# evalsoc register map
Vendor: Nuclei; Series: Nuclei Evaluation SoC
CPU: Evalsoc, little endian
Registers are 32-bit, read-write, reset 0x0 unless marked. A register's access mark holds for its fields unless they carry their own. Offsets are from the block's base; [hi:lo] are bit positions; {n}, {i} and the like mark numbered series.

## TIMER — Address space of TIMER unit. The Timer Unit (TIMER) is used to generate the Timer Interrupt and Software Interrupt in Nuclei Processor Core.
Base 0x18030000
0x00 mtime_lo — Reflect the lower 32-bit value of mtime. Shadow copy of MTIME in CLINT mode.
  [31:0] mtime_lo — Lower 32-bit value of mtime.
0x04 mtime_hi — Reflect the upper 32-bit value of mtime. Shadow copy of MTIME in CLINT mode.
  [31:0] mtime_hi — Upper 32-bit value of mtime.
0x08 mtimecmp_lo — Set the lower 32-bit value of mtimecmp. Shadow copy of MTIMECMP for 1st hart in CLINT mode.
  [31:0] mtimecmp_lo — Lower 32-bit value of mtimecmp.
0x0C mtimecmp_hi — Set the upper 32-bit value of mtimecmp. Shadow copy of MTIMECMP for 1st hart in CLINT mode.
  [31:0] mtimecmp_hi — Upper 32-bit value of mtimecmp.
0xFEC mtime_srw_ctrl — Control S-mode can access timer registers or not.
  [0] SRW — 0: S-Mode can read/write timer registers, 1: S-Mode cannot read/write timer registers
0xFF0 msftrst — Generate soft-reset request.
  [31] MSFTRST — Write 0x80000a5f to generate Soft-Reset Request.
0xFF4 setssip wo — Generate the S-mode Software Interrupt for the local hart.
  [31:0] setssip — Write 1 to trigger edge Supervisor Software Interrupt, read returns 0.
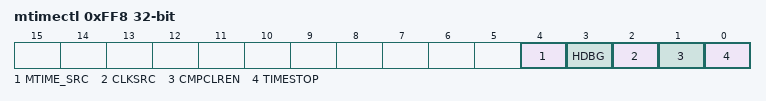
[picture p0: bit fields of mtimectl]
0xFF8 mtimectl — Control the behaviors of timer counting.
  [4] MTIME_SRC — MTIME source select. 0: timer unit mtime, 1: Soc mtime.
  [3] HDBG — Halt-on-debug control. When set, stoptime in dcsr halts the timer counter in debug mode.
  [2] CLKSRC — 1: core_aon_clk, 0: mtime_toggle_a
  [1] CMPCLREN — 1: mtime cleared to zero after timer interrupt, 0: mtime increments normally
  [0] TIMESTOP — 1: timer paused, 0: timer increments normally
0xFFC msip — Generate the M-mode Software Interrupt for the local hart.
  [0] MSIP — Write 1 to generate M-mode software interrupt, write 0 to clear.
{0x1000+4i} msip{i} (i=0..7) — M-mode Software Interrupt for Hart {i}.
  [31:0] MSIP — Write 1 to generate M-mode software interrupt for Hart {i}, write 0 to clear.
{0x5000+8i} mtimecmp{i} 64-bit (reset mask 0xFFFFFFFF) (i=0..7) — M-mode timer compare register for Hart {i}.
  [63:0] mtimecmp — Timer compare value for Hart {i}. When mtime >= mtimecmp, timer interrupt is generated.
0xCFF8 mtime 64-bit (reset mask 0xFFFFFFFF) — MTIME register in CLINT mode.
  [63:0] mtime — 64-bit timer counter value.
{0xD000+4i} setssip{i} wo (i=0..7) — Set Supervisor Software Interrupt request for Hart {i}.
  [31:0] SETSSIP — Write 1 to trigger edge Supervisor Software Interrupt for Hart {i}, read returns 0.

## CIDU — Address space of CIDU unit. The Cluster Interrupt Distribution Unit (CIDU) is used to distribute external interrupts to the core's ECLIC, also provides Inter Core Interrupt (ICI) and Semaphores Mechanism.
Base 0x18050000
{0x0+4i} CORE{i}_INT_STATUS (i=0..7) — Core[i] Inter Core Interrupt status register.
  [15:0] CORE{index}_INT_STATUS — Inter core interrupt status register of core i. Each bit can be cleared by writing 1.
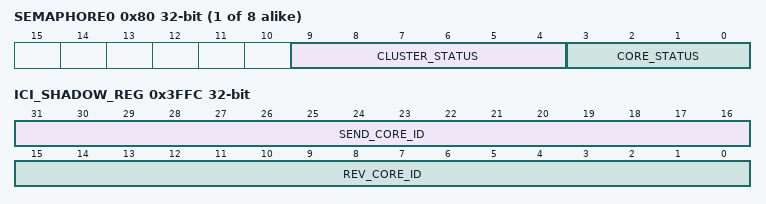
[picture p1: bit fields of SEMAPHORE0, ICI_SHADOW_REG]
{0x80+4i} SEMAPHORE{i} (i=0..7) — Semaphore[i] Inter Core Interrupt Semaphore register. Useful for multi-core cluster without SMP enable.
  [9:4] CLUSTER_STATUS — Reset value is 0x3f, other value means the specific cluster owns the semaphore.
  [3:0] CORE_STATUS — Reset value is 0xf, other value means the specific core owns the semaphore.
0x3FFC ICI_SHADOW_REG wo — ICI Interrupt source core ID and target core ID. Write Only register.
  [31:16] SEND_CORE_ID — The Core ID which sends this Inter Core Interrupt
  [15:0] REV_CORE_ID — The Core ID which receives this Inter Core Interrupt
{0x4000+4i} INT{i}_INDICATOR (i=0..7) — Indicate interrupt i can be received by which cores.
  [15:0] INT{index}_INDICATOR — Each bit indicates the core can receive this interrupt or not. 1 means yes, 0 means no.
{0x8000+4i} INT{i}_MASK (i=0..7) — Mask the INT[i] to the cores or not when the INT[i] Indicator is on.
  [15:0] INT{index}_MASK — Each bit indicates it should mask the indicator bit or not. 1 means no, 0 means yes. Can only be written when its value is all 1 or be written as all 1.
0xC084 CORE_NUM ro — Indicate the static configuration core num in the cluster.
  [31:0] CORE_NUM — Static configuration core num in the cluster.
0xC090 INT_NUM ro — Indicate the static configuration interrupt number.
  [31:0] INT_NUM — Static configuration interrupt number.
0xC09C CIDU_SRW_CTRL — Control S-mode can access this CIDU register or not. Only accessible by M-mode.
  [0] SRW — Control S-mode can read or write CIDU registers or not.<br>0: S-Mode can read/write all CIDU registers.<br>1: S-Mode can not read/write CIDU registers
